# STM32G564 register map
File version: 2.0.0
CPU: CM33 r0p4, little endian, MPU, FPU, 4 interrupt priority bits
Registers are 32-bit, read-write, reset 0x0 unless marked. A register's access mark holds for its fields unless they carry their own. Offsets are from the block's base; [hi:lo] are bit positions; {n}, {i} and the like mark numbered series; 'fields as' and 'values as' point back to an identical list.

## RCC (part 1 of 2) — RCC register block
Base 0x44020C00
Same registers: RCC_S 0x54020C00
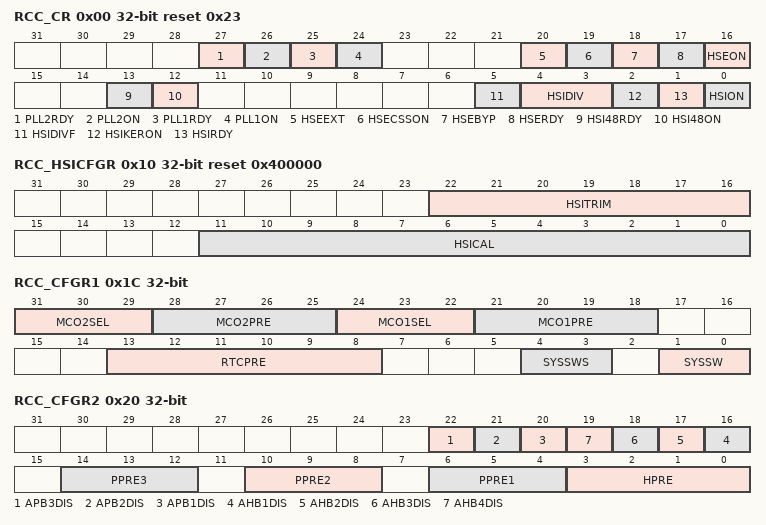
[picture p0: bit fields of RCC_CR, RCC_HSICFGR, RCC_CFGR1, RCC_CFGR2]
0x00 RCC_CR reset 0x23 — RCC clock control register
  [27] PLL2RDY ro — PLL2 clock ready flag
    0=PLL2 unlocked; 1=PLL2 locked
  [26] PLL2ON — PLL2 enable
    0=PLL2 OFF (default after reset); 1=PLL2 ON
  [25] PLL1RDY ro — PLL1 clock ready flag
    0=PLL1 unlocked (default after reset); 1=PLL1 locked
  [24] PLL1ON — PLL1 enable
    0=PLL1 OFF (default after reset); 1=PLL1 ON
  [20] HSEEXT — External high-speed clock type in bypass mode
    0=HSE in analog mode (default after reset); 1=HSE in digital mode
  [19] HSECSSON — HSE clock security system enable
    0=CSS on HSE OFF (clock detector OFF) (default after reset); 1=CSS on HSE ON (clock detector ON if the HSE oscillator is stable, OFF otherwise)
  [18] HSEBYP — HSE clock bypass
    0=HSE oscillator not bypassed (default after reset); 1=HSE oscillator bypassed with an external clock
  [17] HSERDY ro — HSE clock ready flag
    0=HSE clock is not ready (default after reset); 1=HSE clock is ready
  [16] HSEON — HSE clock enable
    0=HSE is OFF (default after reset); 1=HSE is ON
  [13] HSI48RDY ro — HSI48 clock ready flag
    0=HSI48 clock is not ready (default after reset); 1=HSI48 clock is ready
  [12] HSI48ON — HSI48 clock enable
    0=HSI48 is OFF (default after reset); 1=HSI48 is ON
  [5] HSIDIVF ro — HSI divider flag
    0=new division ratio not yet propagated to hsi_ck, hsi_ker_ck (default after reset); 1=hsi_ck, hsi_ker_ck clock frequency reflects the new HSIDIV value (default register value when the clock setting is completed)
  [4:3] HSIDIV — HSI clock divider
    0=division by 1, hsi_ck, hsi_ker_ck=64MHz (default after reset); 1=division by 2, hsi_ck, hsi_ker_ck=32MHz; 2=division by 4, hsi_ck, hsi_ker_ck=16MHz; 3=division by 8, hsi_ck, hsi_ker_ck=8MHz
  [2] HSIKERON — HSI clock enable in Stop mode
    0=no effect on HSI (default after reset); 1=HSI is forced to ON even in Stop mode
  [1] HSIRDY ro — HSI clock ready flag
    0=HSI clock is not ready (default after reset); 1=HSI clock is ready
  [0] HSION — HSI clock enable
    0=HSI is OFF; 1=HSI is ON (default after reset)
0x10 RCC_HSICFGR reset 0x400000 (reset mask 0xFFFFF000) — RCC HSI calibration register
  [22:16] HSITRIM — HSI clock trimming
  [11:0] HSICAL ro — HSI clock calibration
0x14 RCC_CRRCR ro (reset mask 0xFFFFF000) — RCC clock recovery RC register
  [9:0] HSI48CAL — Internal RC 48MHz clock calibration
0x1C RCC_CFGR1 — RCC clock configuration register1
  [31:29] MCO2SEL — microcontroller clock output 2
    0=system clock selected (sys_ck) (default after reset); 1=PLL2 oscillator clock selected (pll2_p_ck); 2=HSE clock selected (hse_ck); 3=PLL1 clock selected (pll1_p_ck); 4=LSI clock selected (lsi_ck)
  [28:25] MCO2PRE — MCO2 prescaler
    0=prescaler disabled, no clock output on MCO2 (default after reset); 1=division by 1 (bypass); 2=division by 2; 3=division by 3; 4=division by 4; 15=division by 15
  [24:22] MCO1SEL — Microcontroller clock output 1
    0=HSI clock selected (hsi_ck) (default after reset); 1=LSE oscillator clock selected (lse_ck); 2=HSE clock selected (hse_ck); 3=PLL1 clock selected (pll1_q_ck); 4=HSI48 clock selected (hsi48_ker_ck)
  [21:18] MCO1PRE — MCO1 prescaler
    0=prescaler disabled, no clock output on MCO1 (default after reset); 1=division by 1 (bypass); 2=division by 2; 3=division by 3; 4=division by 4; 15=division by 15
  [13:8] RTCPRE — HSE division factor for RTC clock
    0=no clock (default after reset); 1=no clock; 2=HSE/2; 3=HSE/3; 4=HSE/4; 62=HSE/62; 63=HSE/63
  [4:3] SYSSWS ro — system clock switch status
    0=HSI used as system clock (hsi_ck) (default after reset); 1=HSE used as system clock (hse_ck); 2=PLL1 used as system clock (pll1_p_ck)
  [1:0] SYSSW — system clock and trace clock switch
    0=HSI selected as system clock (hsi_ck) (default after reset); 1=HSE selected as system clock (hse_ck); 2=PLL1 selected as system clock (pll1_p_ck)
0x20 RCC_CFGR2 — RCC CPU domain clock configuration register 2
  [22] APB3DIS — APB3 clock disable value
    0=APB3 clock enabled, distributed to peripherals according to their dedicated clock enable control bits; 1=APB3 clock disabled
  [21] APB2DIS — APB2 clock disable value
    0=APB2 clock enabled, distributed to peripherals according to their dedicated clock enable control bits; 1=APB2 clock disabled
  [20] APB1DIS — APB1 clock disable value
    0=APB1 clock enabled, distributed to peripherals according to their dedicated clock enable control bits; 1=APB1 clock disabled
  [n+15] AHB{n}DIS (n=1..4) — AHB{n} clock disable
    0=AHB{n} clock enabled, distributed to peripherals according to their dedicated clock enable control bits; 1=AHB{n} clock disabled
  [14:12] PPRE3 — APB low-speed prescaler (APB3)
    4=rcc_pclk3=rcc_hclk1 / 2; 5=rcc_pclk3=rcc_hclk1 / 4; 6=rcc_pclk3=rcc_hclk1 / 8; 7=rcc_pclk3=rcc_hclk1 / 16
  [10:8] PPRE2 — APB high-speed prescaler (APB2)
    4=rcc_pclk2=rcc_hclk1 / 2; 5=rcc_pclk2=rcc_hclk1 / 4; 6=rcc_pclk2=rcc_hclk1 / 8; 7=rcc_pclk2=rcc_hclk1 / 16
  [6:4] PPRE1 — APB low-speed prescaler (APB1)
    4=rcc_pclk1=rcc_hclk1 / 2; 5=rcc_pclk1=rcc_hclk1 / 4; 6=rcc_pclk1=rcc_hclk1 / 8; 7=rcc_pclk1=rcc_hclk1 / 16
  [3:0] HPRE — AHB prescaler
    8=rcc_hclk=sys_ck / 2; 9=rcc_hclk=sys_ck / 4; 10=rcc_hclk=sys_ck / 8; 11=rcc_hclk=sys_ck / 16; 12=rcc_hclk=sys_ck / 64; 13=rcc_hclk=sys_ck / 128; 14=rcc_hclk=sys_ck / 256; 15=rcc_hclk=sys_ck / 512
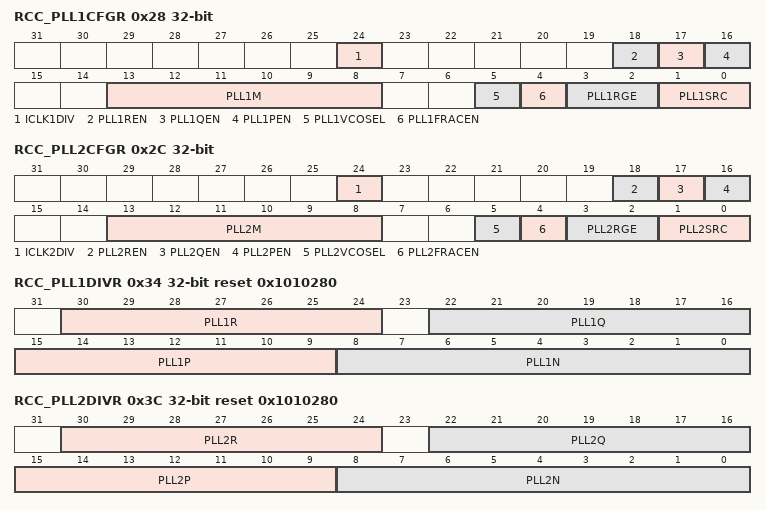
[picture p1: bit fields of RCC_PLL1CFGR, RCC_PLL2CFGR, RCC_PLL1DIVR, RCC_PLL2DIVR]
0x28 RCC_PLL1CFGR — RCC PLL clock source selection register
  [24] ICLK1DIV — Intermediate clock 1 division
    0=Intermediate clock 1 division ratio is 5 (default after reset); 1=Intermediate clock 1 division ratio is 3
  [18] PLL1REN — PLL1 DIVR and ICLK1 divider output enable
    0=pll1_r_ck and ic1_ck outputs disabled (default after reset); 1=pll1_r_ck and ic1_ck outputs enabled
  [17] PLL1QEN — PLL1 DIVQ divider output enable
    0=pll1_q_ck output disabled (default after reset); 1=pll1_q_ck output enabled
  [16] PLL1PEN — PLL1 DIVP divider output enable
    0=pll1_p_ck output disabled (default after reset); 1=pll1_p_ck output enabled
  [13:8] PLL1M — Prescaler for PLL1
    0=prescaler disabled (default after reset); 1=division by 1 (bypass); 2=division by 2; 3=division by 3; 32=division by 32; 63=division by 63
  [5] PLL1VCOSEL — PLL1 VCO selection
    0=wide VCO range: 128 to 560MHz (default after reset); 1=medium VCO range: 150 to 420MHz
  [4] PLL1FRACEN — PLL1 fractional latch enable
  [3:2] PLL1RGE — PLL1 input frequency range
    0=PLL1 input (ref1_ck) clock range frequency between 1 and 2MHz (default after reset); 1=PLL1 input (ref1_ck) clock range frequency between 2 and 4MHz; 2=PLL1 input (ref1_ck) clock range frequency between 4 and 8MHz; 3=PLL1 input (ref1_ck) clock range frequency between 8 and 16MHz
  [1:0] PLL1SRC — PLL1M and PLLs clock source selection
    0=no clock sent to PLL1M divider and PLL1 (default after reset); 1=HSI selected as PLL clock (hsi_ck); 2=HSE selected as PLL clock (hse_ck); 3=no clock sent to PLL1M divider and PLL1
0x2C RCC_PLL2CFGR — RCC PLL clock source selection register
  [24] ICLK2DIV — Intermediate clock 2 division
    0=Intermediate clock 2 division ratio is 5 (default after reset); 1=Intermediate clock 2 division ratio is 3
  [18] PLL2REN — PLL2 DIVR and ICLK2 divider output enable
    0=pll2_r_ck and ic2_ck output disabled (default after reset); 1=pll2_r_ck and ic2_ck outputs enabled
  [17] PLL2QEN — PLL2 DIVQ divider output enable
    0=pll2_q_ck output disabled (default after reset); 1=pll2_q_ck output enabled
  [16] PLL2PEN — PLL2 DIVP divider output enable
    0=pll2_p_ck output disabled (default after reset); 1=pll2_p_ck output enabled
  [13:8] PLL2M — prescaler for PLL2
    values as RCC_PLL1CFGR.PLL1M
  [5] PLL2VCOSEL — PLL2 VCO selection
    values as RCC_PLL1CFGR.PLL1VCOSEL
  [4] PLL2FRACEN — PLL2 fractional latch enable
  [3:2] PLL2RGE — PLL2 input frequency range
    0=PLL2 input (ref2_ck) clock range frequency between 1 and 2MHz (default after reset) 01: PLL2 input (ref2_ck) clock range frequency between 2 and 4MHz; 2=PLL2 input (ref2_ck) clock range frequency between 4 and 8MHz; 3=PLL2 input (ref2_ck) clock range frequency between 8 and 16MHz
  [1:0] PLL2SRC — PLL2 clock source selection
    0=no clock send to PLL2M divider and PLL2 (default after reset); 1=HSI selected as PLL2 clock (hsi_ck); 2=HSE selected as PLL2 clock (hse_ck); 3=no clock send to PLL2M divider and PLL2
0x34 RCC_PLL1DIVR reset 0x1010280 — RCC PLL1 divider register
  [30:24] PLL1R — PLL1 DIVR division factor
    0=pll1_r_ck=vco1_ck / 1; 1=pll1_r_ck=vco1_ck / 2 (default after reset); 2=pll1_r_ck=vco1_ck / 3; 3=pll1_r_ck=vco1_ck / 4; 127=pll1_r_ck=vco1_ck / 128
  [22:16] PLL1Q — PLL1 DIVQ division factor
    0=pll1_q_ck=vco1_ck; 1=pll1_q_ck=vco1_ck / 2 (default after reset); 2=pll1_q_ck=vco1_ck / 3; 3=pll1_q_ck=vco1_ck / 4; 127=pll1_q_ck=vco1_ck / 128
  [15:9] PLL1P — PLL1 DIVP division factor
    0=Not allowed; 1=pll1_p_ck=vco1_ck / 2 (default after reset); 2=Not allowed; 3=pll1_p_ck=vco1_ck / 4; 127=pll1_p_ck=vco1_ck / 128
  [8:0] PLL1N — Multiplication factor for PLL1VCO
    3=PLL1N=4; 4=PLL1N=5; 5=PLL1N=6; 128=PLL1N=129 (default after reset); 0x1FF=PLL1N=512
0x38 RCC_PLL1FRACR — RCC PLL1 fractional divider register
  [15:3] PLL1FRACN — Fractional part of the multiplication factor for PLL1 VCO
0x3C RCC_PLL2DIVR reset 0x1010280 — RCC PLL2 divider register
  [30:24] PLL2R — PLL2 DIVR division factor
    0=pll2_r_ck=vco2_ck; 1=pll2_r_ck=vco2_ck / 2 (default after reset); 2=pll2_r_ck=vco2_ck / 3; 3=pll2_r_ck=vco2_ck / 4; 127=pll2_r_ck=vco2_ck / 128
  [22:16] PLL2Q — PLL2 DIVQ division factor
    0=pll2_q_ck=vco2_ck; 1=pll2_q_ck=vco2_ck / 2 (default after reset); 2=pll2_q_ck=vco2_ck / 3; 3=pll2_q_ck=vco2_ck / 4; 127=pll2_q_ck=vco2_ck / 128
  [15:9] PLL2P — PLL2 DIVP division factor
    0=pll2_p_ck=vco2_ck; 1=pll2_p_ck=vco2_ck / 2 (default after reset); 2=pll2_p_ck=vco2_ck / 3; 3=pll2_p_ck=vco2_ck / 4; 127=pll2_p_ck=vco2_ck / 128
  [8:0] PLL2N — Multiplication factor for PLL2VCO
    3=PLL2N=4; 4=PLL2N=5; 5=PLL2N=6; 128=PLL2N=129 (default after reset); 0x1FF=PLL2N=512
0x40 RCC_PLL2FRACR — RCC PLL2 fractional divider register
  [15:3] PLL2FRACN — fractional part of the multiplication factor for PLL2 VCO
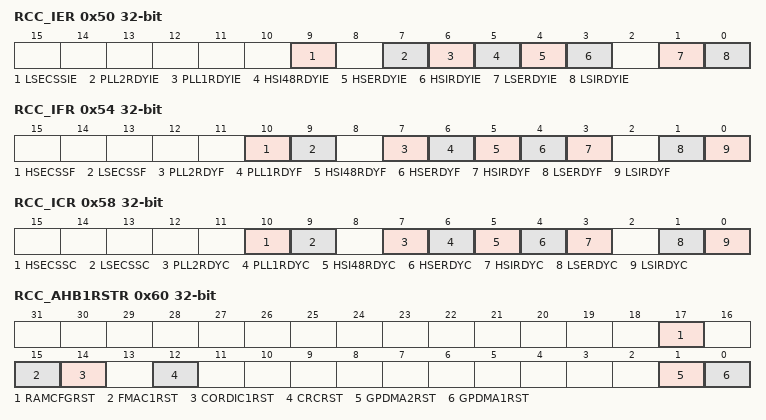
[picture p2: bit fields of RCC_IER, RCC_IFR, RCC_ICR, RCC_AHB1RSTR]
0x50 RCC_IER — RCC interrupt enable register
  [9] LSECSSIE — LSE clock security system interrupt enable
    0=LSE CSS interrupt disabled (default after reset); 1=LSE CSS interrupt enabled
  [7] PLL2RDYIE — PLL2 ready interrupt enable
    0=PLL2 lock interrupt disabled (default after reset); 1=PLL2 lock interrupt enabled
  [6] PLL1RDYIE — PLL1 ready interrupt enable
    0=PLL1 lock interrupt disabled (default after reset); 1=PLL1 lock interrupt enabled
  [5] HSI48RDYIE — HSI48 ready interrupt enable
    0=HSI48 ready interrupt disabled (default after reset); 1=HSI48 ready interrupt enabled
  [4] HSERDYIE — HSE ready interrupt enable
    0=HSE ready interrupt disabled (default after reset); 1=HSE ready interrupt enabled
  [3] HSIRDYIE — HSI ready interrupt enable
    0=HSI ready interrupt disabled (default after reset); 1=HSI ready interrupt enabled
  [1] LSERDYIE — LSE ready interrupt enable
    0=LSE ready interrupt disabled (default after reset); 1=LSE ready interrupt enabled
  [0] LSIRDYIE — LSI ready interrupt enable
    0=LSI ready interrupt disabled (default after reset); 1=LSI ready interrupt enabled
0x54 RCC_IFR ro — RCC interrupt flag register
  [10] HSECSSF — HSE clock security system interrupt flag
    0=no clock security interrupt caused by HSE clock failure (default after reset); 1=clock security interrupt caused by HSE clock failure
  [9] LSECSSF — LSE clock security system interrupt flag
    values as HSECSSF
  [7] PLL2RDYF — PLL2 ready interrupt flag
    0=no clock ready interrupt caused by PLL2 lock (default after reset); 1=clock ready interrupt caused by PLL2 lock
  [6] PLL1RDYF — PLL1 ready interrupt flag
    0=no clock ready interrupt caused by PLL1 lock (default after reset); 1=clock ready interrupt caused by PLL1 lock
  [5] HSI48RDYF — HSI48 ready interrupt flag
    0=no clock ready interrupt caused by the HSI48 oscillator (default after reset); 1=clock ready interrupt caused by the HSI48 oscillator
  [4] HSERDYF — HSE ready interrupt flag
    0=no clock ready interrupt caused by the HSE (default after reset); 1=clock ready interrupt caused by the HSE
  [3] HSIRDYF — HSI ready interrupt flag
    0=no clock ready interrupt caused by the HSI (default after reset); 1=clock ready interrupt caused by the HSI
  [1] LSERDYF — LSE ready interrupt flag
    0=no clock ready interrupt caused by the LSE (default after reset); 1=clock ready interrupt caused by the LSE
  [0] LSIRDYF — LSI ready interrupt flag
    0=no clock ready interrupt caused by the LSI (default after reset); 1=clock ready interrupt caused by the LSI
0x58 RCC_ICR — RCC Interrupt clear register
  [10] HSECSSC — HSE clock security system interrupt clear
    0=HSECSSF no effect (default after reset); 1=HSECSSF cleared
  [9] LSECSSC — LSE clock security system interrupt clear
    0=LSECSSF no effect (default after reset); 1=LSECSSF cleared
  [7] PLL2RDYC — PLL2 ready interrupt clear
    0=PLL2RDYF no effect (default after reset); 1=PLL2RDYF cleared
  [6] PLL1RDYC — PLL1 ready interrupt clear
    0=PLL1RDYF no effect (default after reset); 1=PLL1RDYF cleared
  [5] HSI48RDYC — HSI48 ready interrupt clear
    0=HSI48RDYF no effect (default after reset); 1=HSI48RDYF cleared
  [4] HSERDYC — HSE ready interrupt clear
    0=HSERDYF no effect (default after reset); 1=HSERDYF cleared
  [3] HSIRDYC — HSI ready interrupt clear
    0=HSIRDYF no effect (default after reset); 1=HSIRDYF cleared
  [1] LSERDYC — LSE ready interrupt clear
    0=LSERDYF no effect (default after reset); 1=LSERDYF cleared
  [0] LSIRDYC — LSI ready interrupt clear
    0=LSIRDYF no effect (default after reset); 1=LSIRDYF cleared
0x60 RCC_AHB1RSTR — RCC AHB1 reset register
  [17] RAMCFGRST — RAMCFG block reset
    0=does not reset RAMCFG block (default after reset); 1=resets RAMCFG block
  [15] FMAC1RST — FMAC1 block reset
    0=does not reset FMAC1 block (default after reset); 1=resets FMAC1 block
  [14] CORDIC1RST — CORDIC1 block reset
    0=does not reset CORDIC1 block (default after reset); 1=resets CORDIC1 block
  [12] CRCRST — CRC block reset Set and cleared by software.
    0=does not reset CRC block (default after reset); 1=resets CRC block
  [1] GPDMA2RST — GPDMA2 block reset
    0=does not reset GPDMA2 block (default after reset); 1=resets GPDMA2 block
  [0] GPDMA1RST — GPDMA1 block reset
    0=does not reset GPDMA1 block (default after reset); 1=resets GPDMA1 block
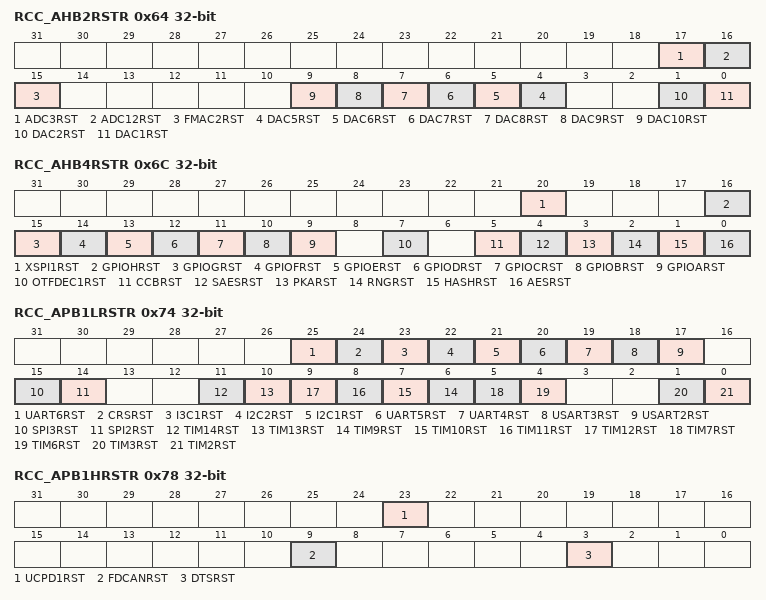
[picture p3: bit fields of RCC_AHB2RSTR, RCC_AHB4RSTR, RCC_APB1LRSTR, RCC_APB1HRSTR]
0x64 RCC_AHB2RSTR — RCC AHB2 peripheral reset register
  [17] ADC3RST — ADC3 blocks reset
    0=does not reset ADC3 blocks (default after reset); 1=resets ADC3 blocks
  [16] ADC12RST — ADC1 and 2 blocks reset
    0=does not reset ADC1 and 2 blocks (default after reset); 1=resets ADC1 and 2 blocks
  [15] FMAC2RST — FMAC2 block reset
    0=does not reset FMAC2 block (default after reset); 1=resets FMAC2 block
  [n-1] DAC{n}RST (n=5..10) — DAC{n} block reset
    0=does not reset DAC{n} block (default after reset); 1=resets DAC{n} block
  [1] DAC2RST — DAC2 block reset
    0=does not reset DAC2 block (default after reset); 1=resets DAC2 block
  [0] DAC1RST — DAC1 block reset
    0=does not reset DAC1 block (default after reset); 1=resets DAC1 block
0x6C RCC_AHB4RSTR — RCC AHB4 peripheral reset register
  [20] XSPI1RST — XSPI1 block reset
    0=does not reset XSPI1 block (default after reset); 1=resets XSPI1 block
  [16] GPIOHRST — GPIOH block reset
    0=does not reset the GPIOH block (default after reset); 1=resets the GPIOH block
  [15] GPIOGRST — GPIOG block reset
    0=does not reset the GPIOG block (default after reset); 1=resets the GPIOG block
  [14] GPIOFRST — GPIOF block reset
    0=does not reset the GPIOF block (default after reset); 1=resets the GPIOF block
  [13] GPIOERST — GPIOE block reset
    0=does not reset the GPIOE block (default after reset); 1=resets the GPIOE block
  [12] GPIODRST — GPIOD block reset
    0=does not reset the GPIOD block (default after reset); 1=resets the GPIOD block
  [11] GPIOCRST — GPIOC block reset
    0=does not reset the GPIOC block (default after reset); 1=resets the GPIOC block
  [10] GPIOBRST — GPIOB block reset
    0=does not reset the GPIOB block (default after reset); 1=resets the GPIOB block
  [9] GPIOARST — GPIOA block reset
    0=does not reset the GPIOA block (default after reset); 1=resets the GPIOA block
  [7] OTFDEC1RST — OTFDEC1 block reset
    0=does not reset OTFDEC1 block (default after reset); 1=resets OTFDEC1 block
  [5] CCBRST — CCB block reset
    0=does not reset CCB block (default after reset); 1=resets CCB block
  [4] SAESRST — SAES block reset
    0=does not reset SAES block (default after reset); 1=resets SAES block
  [3] PKARST — PKA block reset
    0=does not reset PKA block (default after reset); 1=resets PKA block
  [2] RNGRST — RNG block reset
    0=does not reset RNG block (default after reset); 1=resets RNG block
  [1] HASHRST — HASH block reset
    0=does not reset HASH block (default after reset); 1=resets HASH block
  [0] AESRST — AES block reset
    0=does not reset AES block (default after reset); 1=resets AES block
0x74 RCC_APB1LRSTR — RCC APB1 peripheral low reset register
  [25] UART6RST — UART6 block reset
    0=does not reset the UART6 block (default after reset); 1=resets the UART6 block
  [24] CRSRST — CRS block reset
    0=does not reset the CRS block (default after reset); 1=resets the CRS block
  [23] I3C1RST — I3C1 block reset
    0=does not reset the I3C1 block (default after reset); 1=resets the I3C1 block
  [22] I2C2RST — I2C2 block reset
    0=does not reset the I2C2 block (default after reset); 1=resets the I2C2 block
  [21] I2C1RST — I2C1 block reset
    0=does not reset the I2C1 block (default after reset); 1=resets the I2C1 block
  [20] UART5RST — UART5 block reset
    0=does not reset the UART5 block (default after reset); 1=resets the UART5 block
  [19] UART4RST — UART4 block reset
    0=does not reset the UART4 block (default after reset); 1=resets the UART4 block
  [18] USART3RST — USART3 block reset
    0=does not reset the USART3 block (default after reset); 1=resets the USART3 block
  [17] USART2RST — USART2 block reset
    0=does not reset the USART2 block (default after reset); 1=resets the USART2 block
  [15] SPI3RST — SPI3 block reset
    0=does not reset the SPI3 block (default after reset); 1=resets the SPI3 block
  [14] SPI2RST — SPI2 block reset
    0=does not reset the SPI2 block (default after reset); 1=resets the SPI2 block
  [11] TIM14RST — TIM14 block reset
    0=does not reset the TIM14 block (default after reset); 1=resets the TIM14 block
  [10] TIM13RST — TIM13 block reset
    0=does not reset the TIM13 block (default after reset); 1=resets the TIM13 block
  [n-3] TIM{n}RST (n=9..12) — TIM12 block reset
    0=does not reset the TIM12 block (default after reset); 1=resets the TIM12 block
  [5] TIM7RST — TIM7 block reset
    0=does not reset the TIM7 block (default after reset); 1=resets the TIM7 block
  [4] TIM6RST — TIM6 block reset
    0=does not reset the TIM6 block (default after reset); 1=resets the TIM6 block
  [1] TIM3RST — TIM3 block reset
    0=does not reset the TIM3 block (default after reset); 1=resets the TIM3 block
  [0] TIM2RST — TIM2 block reset
    0=does not reset the TIM2 block (default after reset); 1=resets the TIM2 block
0x78 RCC_APB1HRSTR — RCC APB1 peripheral high reset register
  [23] UCPD1RST — UCPD1 block reset
    0=does not reset the UCPD1 block (default after reset); 1=resets the UCPD1 block
  [9] FDCANRST — FDCAN1, FDCAN2 and FDCAN3 block reset
    0=does not reset the FDCAN1, FDCAN2 and FDCAN3 blocks (default after reset); 1=resets the FDCAN1, FDCAN2 and FDCAN3 blocks
  [3] DTSRST — DTS block reset
    0=does not reset the DTS block (default after reset); 1=resets the DTS block
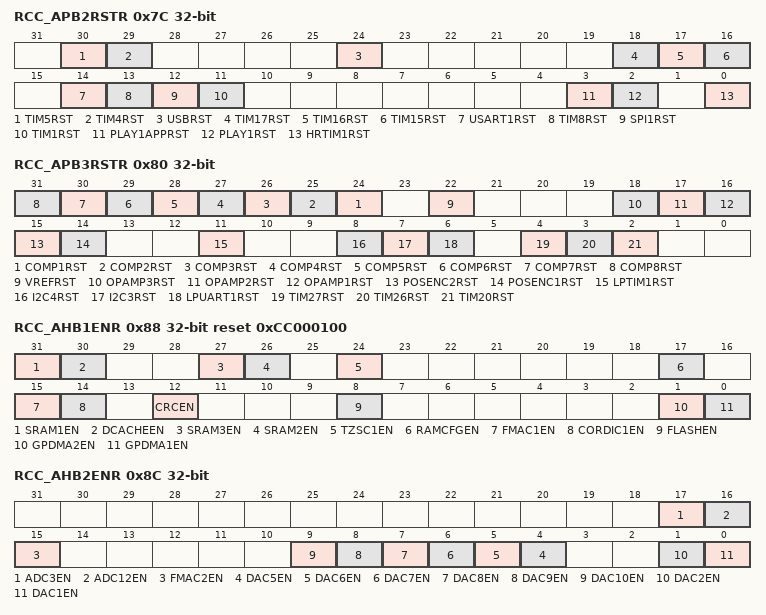
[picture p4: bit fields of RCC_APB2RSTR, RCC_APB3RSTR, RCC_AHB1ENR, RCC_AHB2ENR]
0x7C RCC_APB2RSTR — RCC APB2 peripheral reset register
  [30] TIM5RST — TIM5 block reset
    0=does not reset the TIM5 block (default after reset); 1=resets the TIM5 block
  [29] TIM4RST — TIM4 block reset
    0=does not reset the TIM4 block (default after reset); 1=resets the TIM4 block
  [24] USBRST — USB block reset
    0=does not reset the USB block (default after reset); 1=resets the USB block
  [18] TIM17RST — TIM17 block reset
    0=does not reset the TIM17 block (default after reset); 1=resets the TIM17 block
  [17] TIM16RST — TIM16 block reset
    0=does not reset the TIM16 block (default after reset); 1=resets the TIM16 block
  [16] TIM15RST — TIM15 block reset
    0=does not reset the TIM15 block (default after reset); 1=resets the TIM15 block
  [14] USART1RST — USART1 block reset
    0=does not reset the USART1 block (default after reset); 1=resets the USART1 block
  [13] TIM8RST — TIM8 block reset
    0=does not reset the TIM8 block (default after reset); 1=resets the TIM8 block
  [12] SPI1RST — SPI1 block reset
    0=does not reset the SPI1 block (default after reset); 1=resets the SPI1 block
  [11] TIM1RST — TIM1 block reset
    0=does not reset the TIM1 block (default after reset); 1=resets the TIM1 block
  [3] PLAY1APPRST — PLAY1 application block reset
    0=does not reset PLAY1 block (default after reset); 1=resets PLAY1 block
  [2] PLAY1RST — PLAY1 global block reset
    values as PLAY1APPRST
  [0] HRTIM1RST — HRTIM1 block reset
    0=does not reset the HRTIM1 block (default after reset); 1=resets the HRTIM1 block
0x80 RCC_APB3RSTR — RCC APB3 peripheral reset register
  [n+23] COMP{n}RST (n=1..8) — COMP{n} block reset
    0=does not reset the COMP{n} block (default after reset); 1=resets the COMP{n} block
  [22] VREFRST — VREFBUF block reset
    0=does not reset the VREFBUF block (default after reset); 1=resets the VREFBUF block
  [18] OPAMP3RST — OPAMP3 block reset
    0=does not reset the OPAMP3 block (default after reset); 1=resets the OPAMP3 block
  [17] OPAMP2RST — OPAMP2 block reset
    0=does not reset the OPAMP2 block (default after reset); 1=resets the OPAMP2 block
  [16] OPAMP1RST — OPAMP1 block reset
    0=does not reset the OPAMP1 block (default after reset); 1=resets the OPAMP1 block
  [15] POSENC2RST — POSENC2 block reset
    0=does not reset the POSENC2 block (default after reset); 1=resets the POSENC2 block
  [14] POSENC1RST — POSENC1 block reset
    0=does not reset the POSENC1 block (default after reset); 1=resets the POSENC1 block
  [11] LPTIM1RST — LPTIM1 block reset
    0=does not reset the LPTIM1 block (default after reset); 1=resets the LPTIM1 block
  [8] I2C4RST — I2C4 block reset
    0=does not reset the I2C4 block (default after reset); 1=resets the I2C4 block
  [7] I2C3RST — I2C3 block reset
    0=does not reset the I2C3 block (default after reset); 1=resets the I2C3 block
  [6] LPUART1RST — LPUART1 block reset
    0=does not reset the LPUART1 block (default after reset); 1=resets the LPUART1 block
  [4] TIM27RST — TIM27 block reset
    0=does not reset the TIM27 block (default after reset); 1=resets the TIM27 block
  [3] TIM26RST — TIM26 block reset
    0=does not reset the TIM26 block (default after reset); 1=resets the TIM26 block
  [2] TIM20RST — TIM20 block reset
    0=does not reset the TIM20 block (default after reset); 1=resets the TIM20 block
0x88 RCC_AHB1ENR reset 0xCC000100 — RCC AHB1 peripheral clock enable register
  [31] SRAM1EN — SRAM1 clock enable
    0=SRAM1 clock disabled; 1=SRAM1 clock enabled (default after reset)
  [30] DCACHEEN — DCACHE clock enable
    0=DCACHE peripheral clock disabled; 1=DCACHE peripheral clock enabled (default after reset)
  [27] SRAM3EN — SRAM3 clock enable
    0=SRAM3 clock disabled; 1=SRAM3 clock enabled (default after reset)
  [26] SRAM2EN — SRAM2 clock enable
    0=SRAM2 clock disabled; 1=SRAM2 clock enabled (default after reset)
  [24] TZSC1EN — TZSC1 clock enable
    0=TZSC1 peripheral clock disabled (default after reset); 1=TZSC1 peripheral clock enabled
  [17] RAMCFGEN — RAMCFG clock enable
    0=RAMCFG peripheral clock disabled (default after reset); 1=RAMCFG peripheral clock enabled
  [15] FMAC1EN — FMAC1 clock enable
    0=FMAC1 peripheral clock disabled (default after reset); 1=FMAC1 peripheral clock enabled
  [14] CORDIC1EN — CORDIC1 clock enable
    0=CORDIC1 peripheral clock disabled (default after reset); 1=CORDIC1 peripheral clock enable
  [12] CRCEN — CRC clock enable
    0=CRC peripheral clock disabled (default after reset); 1=CRC peripheral clock enabled
  [8] FLASHEN — Flash memory interface clock enable
    0=Flash memory interface clock disabled; 1=Flash memory interface clock enabled (default after reset)
  [1] GPDMA2EN — GPDMA2 clock enable
    0=GPDMA2 peripheral clock disabled (default after reset); 1=GPDMA2 peripheral clock enabled
  [0] GPDMA1EN — GPDMA1 clock enable
    0=GPDMA1 peripheral clock disabled (default after reset); 1=GPDMA1 peripheral clock enabled
0x8C RCC_AHB2ENR — RCC AHB2 peripheral clock enable register
  [17] ADC3EN — ADC3 peripheral clocks enable
    0=ADC3 peripheral clocks disabled (default after reset); 1=ADC3 peripheral clocks enabled
  [16] ADC12EN — ADC1 and ADC2 peripheral clocks enable
    0=ADC1 and ADC2 peripheral clocks disabled (default after reset); 1=ADC1 and ADC2 peripheral clocks enabled
  [15] FMAC2EN — FMAC2 clock enable
    0=FMAC2 peripheral clock disabled (default after reset); 1=FMAC2 peripheral clock enabled
  [n-1] DAC{n}EN (n=5..10) — DAC{n} clock enable
    0=DAC{n} peripheral clock disabled (default after reset); 1=DAC{n} peripheral clock enabled
  [1] DAC2EN — DAC2 clock enable
    0=DAC2 peripheral clock disabled (default after reset); 1=DAC2 peripheral clock enabled
  [0] DAC1EN — DAC1 clock enable
    0=DAC1 peripheral clock disabled (default after reset); 1=DAC1 peripheral clock enabled
0x90 RCC_AHB3ENR — RCC AHB3 peripheral clock enable register
  [21] DBGCKEN — DBG clock enable
    0=DBG clock disabled (default after reset); 1=DBG clock enabled
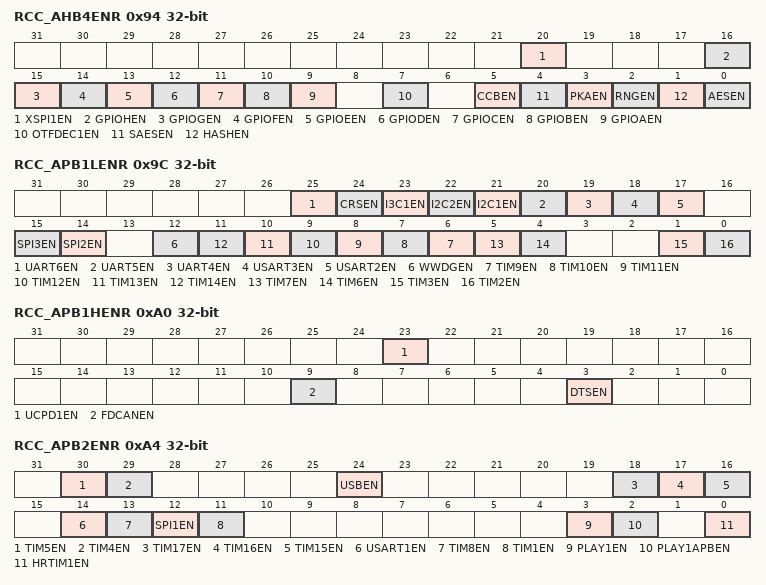
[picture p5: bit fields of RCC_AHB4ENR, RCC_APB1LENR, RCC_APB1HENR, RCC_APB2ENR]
0x94 RCC_AHB4ENR — RCC AHB4 peripheral clock enable register
  [20] XSPI1EN — XSPI1 clock enable
    0=XSPI1 peripheral clock disabled (default after reset); 1=XSPI1 peripheral clock enabled
  [16] GPIOHEN — GPIOH clock enable
    0=GPIOH peripheral clock disabled (default after reset); 1=GPIOH peripheral clock enabled
  [15] GPIOGEN — GPIOG clock enable
    0=GPIOG peripheral clock disabled (default after reset); 1=GPIOG peripheral clock enabled
  [14] GPIOFEN — GPIOF clock enable
    0=GPIOF peripheral clock disabled (default after reset); 1=GPIOF peripheral clock enabled
  [13] GPIOEEN — GPIOE clock enable
    0=GPIOE peripheral clock disabled (default after reset); 1=GPIOE peripheral clock enabled
  [12] GPIODEN — GPIOD clock enable
    0=GPIOD peripheral clock disabled (default after reset); 1=GPIOD peripheral clock enabled
  [11] GPIOCEN — GPIOC clock enable
    0=GPIOC peripheral clock disabled (default after reset); 1=GPIOC peripheral clock enabled
  [10] GPIOBEN — GPIOB clock enable
    0=GPIOB peripheral clock disabled (default after reset); 1=GPIOB peripheral clock enabled
  [9] GPIOAEN — GPIOA clock enable
    0=GPIOA peripheral clock disabled (default after reset); 1=GPIOA peripheral clock enabled
  [7] OTFDEC1EN — OTFDEC1 clock enable
    0=OTFDEC1 peripheral clock disabled (default after reset); 1=OTFDEC1 peripheral clock enabled
  [5] CCBEN — CCB clock enable
    0=CCB peripheral clock disabled (default after reset); 1=CCB peripheral clock enabled
  [4] SAESEN — SAES clock enable
    0=SAES peripheral clock disabled (default after reset); 1=SAES peripheral clock enabled
  [3] PKAEN — PKA clock enable
    0=PKA peripheral clock disabled (default after reset); 1=PKA peripheral clock enabled
  [2] RNGEN — RNG clock enable
    0=RNG peripheral clock disabled (default after reset); 1=RNG peripheral clock enabled
  [1] HASHEN — HASH clock enable
    0=HASH peripheral clock disabled (default after reset); 1=HASH peripheral clock enabled
  [0] AESEN — AES clock enable
    0=AES peripheral clock disabled (default after reset); 1=AES peripheral clock enabled
0x9C RCC_APB1LENR — RCC APB1 peripheral clock enable register
  [25] UART6EN — UART6 clock enable
    0=UART6 peripheral clock disabled (default after reset); 1=UART6 peripheral clock enabled
  [24] CRSEN — CRS clock enable
    0=CRS peripheral clock disabled (default after reset); 1=CRS peripheral clock enabled
  [23] I3C1EN — I3C1 clock enable
    0=I3C1 peripheral clock disabled (default after reset); 1=I3C1 peripheral clock enabled
  [22] I2C2EN — I2C2 clock enable
    0=I2C2 peripheral clock disabled (default after reset); 1=I2C2 peripheral clock enabled
  [21] I2C1EN — I2C1 clock enable
    0=I2C1 peripheral clock disabled (default after reset); 1=I2C1 peripheral clock enabled
  [20] UART5EN — UART5 clock enable
    0=UART5 peripheral clock disabled (default after reset); 1=UART5 peripheral clock enabled
  [19] UART4EN — UART4 clock enable
    0=UART4 peripheral clock disabled (default after reset); 1=UART4 peripheral clock enabled
  [18] USART3EN — USART3 clock enable
    0=USART3 peripheral clock disabled (default after reset); 1=USART3 peripheral clock enabled
  [17] USART2EN — USART2 clock enable
    0=USART2 peripheral clock disabled (default after reset); 1=USART2 peripheral clock enabled
  [15] SPI3EN — SPI3 clock enable
    0=SPI3 peripheral clock disabled (default after reset); 1=SPI3 peripheral clock enabled
  [14] SPI2EN — SPI2 clock enable
    0=SPI2 peripheral clock disabled (default after reset); 1=SPI2 peripheral clock enabled
  [12] WWDGEN — WWDG clock enable
    0=WWDG peripheral clock disabled (default after reset); 1=WWDG peripheral clock enabled
  [n-3] TIM{n}EN (n=9..14) — TIM{n} clock enable
    0=TIM{n} peripheral clock disabled (default after reset); 1=TIM{n} peripheral clock enabled
  [5] TIM7EN — TIM7 clock enable
    0=TIM7 peripheral clock disabled (default after reset); 1=TIM7 peripheral clock enabled
  [4] TIM6EN — TIM6 clock enable
    0=TIM6 peripheral clock disabled (default after reset); 1=TIM6 peripheral clock enabled
  [1] TIM3EN — TIM3 clock enable
    0=TIM3 peripheral clock disabled (default after reset); 1=TIM3 peripheral clock enabled
  [0] TIM2EN — TIM2 clock enable
    0=TIM2 peripheral clock disabled (default after reset); 1=TIM2 peripheral clock enabled
0xA0 RCC_APB1HENR — RCC APB1 peripheral clock enable register
  [23] UCPD1EN — UCPD1 clock enable
    0=UCPD1 peripheral clock disabled (default after reset); 1=UCPD1 peripheral clock enabled
  [9] FDCANEN — FDCAN1, FDCAN2 and FDCAN3 peripheral clock enable
    0=FDCAN1, FDCAN2 and FDCAN3 peripheral clock disabled (default after reset); 1=FDCAN1, FDCAN2 and FDCAN3 peripheral clock enabled
  [3] DTSEN — DTS clock enable
    0=DTS peripheral clock disabled (default after reset); 1=DTS peripheral clock enabled
0xA4 RCC_APB2ENR — RCC APB2 peripheral clock enable register
  [30] TIM5EN — TIM5 clock enable
    0=TIM5 peripheral clock disabled (default after reset); 1=TIM5 peripheral clock enabled
  [29] TIM4EN — TIM4 clock enable
    0=TIM4 peripheral clock disabled (default after reset); 1=TIM4 peripheral clock enabled
  [24] USBEN — USB clock enable
    0=USB peripheral clock disabled (default after reset); 1=USB peripheral clock enabled
  [18] TIM17EN — TIM17 clock enable
    0=TIM17 peripheral clock disabled (default after reset); 1=TIM17 peripheral clock enabled
  [17] TIM16EN — TIM16 clock enable
    0=TIM16 peripheral clock disabled (default after reset); 1=TIM16 peripheral clock enabled
  [16] TIM15EN — TIM15 clock enable
    0=TIM15 peripheral clock disabled (default after reset); 1=TIM15 peripheral clock enabled
  [14] USART1EN — USART1 clock enable
    0=USART1 peripheral clock disabled (default after reset); 1=USART1 peripheral clock enabled
  [13] TIM8EN — TIM8 clock enable
    0=TIM8 peripheral clock disabled (default after reset); 1=TIM8 peripheral clock enabled
  [12] SPI1EN — SPI1 clock enable
    0=SPI1 peripheral clock disabled (default after reset); 1=SPI1 peripheral clock enabled
  [11] TIM1EN — TIM1 clock enable
    0=TIM1 peripheral clock disabled (default after reset); 1=TIM1 peripheral clock enabled
  [3] PLAY1EN — PLAY1 clock enable
    0=PLAY1 peripheral clock disabled (default after reset); 1=PLAY1 peripheral clock enabled
  [2] PLAY1APBEN — PLAY1 APB clock enable
    0=PLAY1 APB clock disabled (default after reset); 1=PLAY1 APB clock enabled
  [0] HRTIM1EN — HRTIM1 clock enable
    0=HRTIM1 peripheral clock disabled (default after reset); 1=HRTIM1 peripheral clock enabled
